# SN32F420 register map
Vendor: SONiX Technology Co., Ltd.; Series: SN32F420; File version: 1.00
CPU: CM0 r0p0, little endian, no MPU, no FPU, 2 interrupt priority bits
Registers are 32-bit, read-write, reset 0x0 unless marked. A register's access mark holds for its fields unless they carry their own. Offsets are from the block's base; [hi:lo] are bit positions; {n}, {i} and the like mark numbered series.

## SN_MT16B0 — 16-bit Timer 0 with Mortor Control function
Base 0x40000000
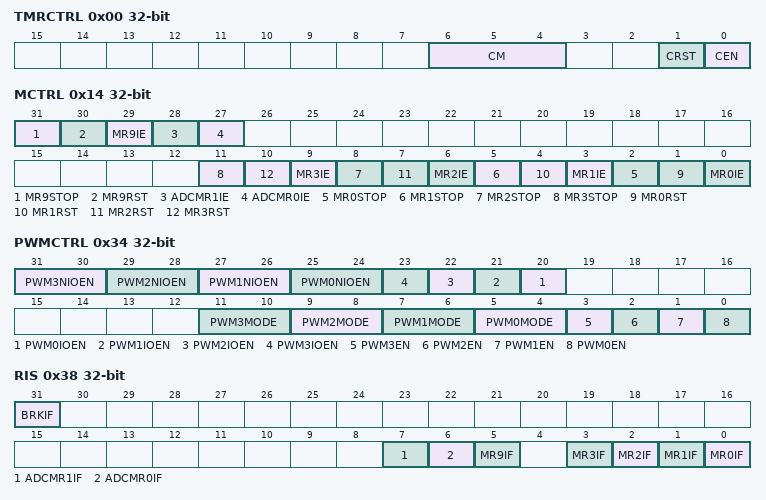
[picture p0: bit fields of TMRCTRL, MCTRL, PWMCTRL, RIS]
0x00 TMRCTRL — Offset:0x00 MT16Bn Timer Control register
  [6:4] CM — Counting mode selection
    0=Up-counting mode (Edge-aligned Up-counting mode); 2=Center-aligned counting mode 1 (The match interrupt flag is set during the down-counting period); 4=Center-aligned counting mode 2 (The match interrupt flag is set during the up-counting period); 6=Center-aligned counting mode 3 (The match interrupt flag is set during both up-counting and down-counting period)
  [1] CRST — Counter Reset
    0=Disable counter reset; 1=Reset Counter (Timer Counter and the Prescale Counter are synchronously reset on the next positive edge of PCLK)
  [0] CEN — Counter enable
    0=Disable counter; 1=Enable Timer Counter and Prescale Counter for counting
0x04 TC — Offset:0x04 MT16Bn Timer Counter register
  [15:0] TC — Timer Counter
0x08 PRE — Offset:0x08 MT16Bn Prescale register
  [7:0] PRE — Prescaler
0x0C PC — Offset:0x0C MT16Bn Prescale Counter register
  [7:0] PC — Prescaler Counter
0x14 MCTRL — Offset:0x14 MT16Bn Match Control register
  [31] MR9STOP — Stop TC and PC and clear CEN bit when MR9 matches TC
    0=Disable stop TC and PC; 1=Enable (Stop TC and PC and clear CEN bit when MR9 matches TC)
  [30] MR9RST — Enable reset TC when MR9 matches TC
    0=Disable reset TC; 1=Enable (Reset TC when MR9 matches TC)
  [29] MR9IE — Enable generating an interrupt based on CM[2:0] when MR9 matches the value in the TC
    0=Disable generating an interrupt; 1=Enable (Generating an interrupt when MR9 matches TC)
  [28] ADCMR1IE — Enable generating an interrupt based on CM[2:0] when TMR1 matches the value in the TC
    0=Disable generating an interrupt; 1=Enable (Generating an interrupt when ADCMR1 matches TC)
  [27] ADCMR0IE — Enable generating an interrupt based on CM[2:0] when TMR0 matches the value in the TC
    0=Disable generating an interrupt; 1=Enable (Generating an interrupt when ADCMR0 matches TC)
  [3n+2] MR{n}STOP (n=0..3) — Stop TC and PC and clear CEN bit when MR{n} matches TC
    0=Disable stop TC and PC; 1=Enable (Stop TC and PC and clear CEN bit when MR{n} matches TC)
  [3n+1] MR{n}RST (n=0..3) — Enable reset TC when MR{n} matches TC
    0=Disable reset TC; 1=Enable (Reset TC when MR{n} matches TC)
  [3n] MR{n}IE (n=0..3) — Enable generating an interrupt when MR{n} matches TC
    0=Disable generating an interrupt; 1=Enable (Generating an interrupt when MR{n} matches TC)
{0x18+4i} MR{i} (i=0..3) — Offset:{0x18+4i} MT16Bn MR{i} register
  [15:0] MR — Timer counter match value
0x34 PWMCTRL — Offset:0x34 MT16Bn PWM Control register
  [31:30] PWM3NIOEN — MT16Bn_PWM3N/GPIO selection bit
    0=GPIO (MT16Bn_PWM3N pin is act as GPIO); 1=Inverse1 (MT16Bn_PWM3N pin outputs the inverse signal with dead-band of MT16Bn_PWM3, but same High signal during dead-band period); 2=Inverse2 (MT16Bn_PWM3N pin outputs the inverse signal with dead-band of MT16Bn_PWM3, but same Low signal during dead-band period); 3=Same (MT16Bn_PWM3N pin outputs the same signal with dead-band of MT16Bn_PWM3)
  [29:28] PWM2NIOEN — MT16Bn_PWM0N/GPIO selection bit
    0=GPIO (MT16Bn_PWM2N pin is act as GPIO); 1=Inverse1 (MT16Bn_PWM2N pin outputs the inverse signal with dead-band of MT16Bn_PWM0, but same High signal during dead-band period); 2=Inverse2 (MT16Bn_PWM2N pin outputs the inverse signal with dead-band of MT16Bn_PWM0, but same Low signal during dead-band period); 3=Same (MT16Bn_PWM2N pin outputs the same signal with dead-band of MT16Bn_PWM0)
  [27:26] PWM1NIOEN — MT16Bn_PWM0N/GPIO selection bit
    0=GPIO (MT16Bn_PWM1N pin is act as GPIO); 1=Inverse1 (MT16Bn_PWM1N pin outputs the inverse signal with dead-band of MT16Bn_PWM0, but same High signal during dead-band period); 2=Inverse2 (MT16Bn_PWM1N pin outputs the inverse signal with dead-band of MT16Bn_PWM0, but same Low signal during dead-band period); 3=Same (MT16Bn_PWM1N pin outputs the same signal with dead-band of MT16Bn_PWM0)
  [25:24] PWM0NIOEN — MT16Bn_PWM0N/GPIO selection bit
    0=GPIO (MT16Bn_PWM0N pin is act as GPIO); 1=Inverse1 (MT16Bn_PWM0N pin outputs the inverse signal with dead-band of MT16Bn_PWM0, but same High signal during dead-band period); 2=Inverse2 (MT16Bn_PWM0N pin outputs the inverse signal with dead-band of MT16Bn_PWM0, but same Low signal during dead-band period); 3=Same (MT16Bn_PWM0N pin outputs the same signal with dead-band of MT16Bn_PWM0)
  [n+20] PWM{n}IOEN (n=0..3) — MT16Bn_PWM{n}/GPIO selection
    0=Disable (MT16Bn_PWM{n} pin is act as GPIO); 1=Enable (MT16Bn_PWM{n} pin act as match output, and output depends on PWM{n}EN bit)
  [2n+5:2n+4] PWM{n}MODE (n=0..3) — PWM{n} output mode
    0=PWM mode 1 (During up-counting, PWM{n} is 0 when TC is less than MR{n}.); 1=PWM mode 2 (During up-counting, PWM{n} is 1 when TC is less than MR{n}.); 2=Force 0 (PWM{n} is forced to 0); 3=Force 1 (PWM{n} is forced to 1)
  [3] PWM3EN — PWM2 enable
    0=Disable PWM mode for MT16Bn_PWM3; 1=Enable PWM mode for MT16Bn_PWM3
  [2] PWM2EN — PWM2 enable
    0=Disable PWM mode for MT16Bn_PWM2; 1=Enable PWM mode for MT16Bn_PWM2
  [1] PWM1EN — PWM1 enable
    0=Disable PWM mode for MT16Bn_PWM0; 1=Enable PWM mode for MT16Bn_PWM1
  [0] PWM0EN — PWM0 enable
    0=Disable PWM mode for MT16Bn_PWM0; 1=Enable PWM mode for MT16Bn_PWM0
0x38 RIS ro — Offset:0x38 MT16Bn Raw Interrupt Status register
  [31] BRKIF — Break interrupt flag
    0=No (No break condition occurs); 1=Met interrupt requirements (Break condition occurs)
  [7] ADCMR1IF — Match value for ADC triggered 1 interrupt flag
    0=No (No interrupt on match value for ADC triggered 1); 1=Met interrupt requirements (Interrupt requirements met on match value for ADC triggered 1)
  [6] ADCMR0IF — Match value for ADC triggered 0 interrupt flag
    0=No (No interrupt on match value for ADC triggered 0); 1=Met interrupt requirements (Interrupt requirements met on match value for ADC triggered 0)
  [5] MR9IF — Match channel 9 interrupt flag
    0=No (No interrupt on match channel 9); 1=Met interrupt requirements (Interrupt requirements met on match channel 9)
  [n] MR{n}IF (n=0..3) — Match channel {n} interrupt flag
    0=No (No interrupt on match channel {n}); 1=Met interrupt requirements (Interrupt requirements met on match channel {n})
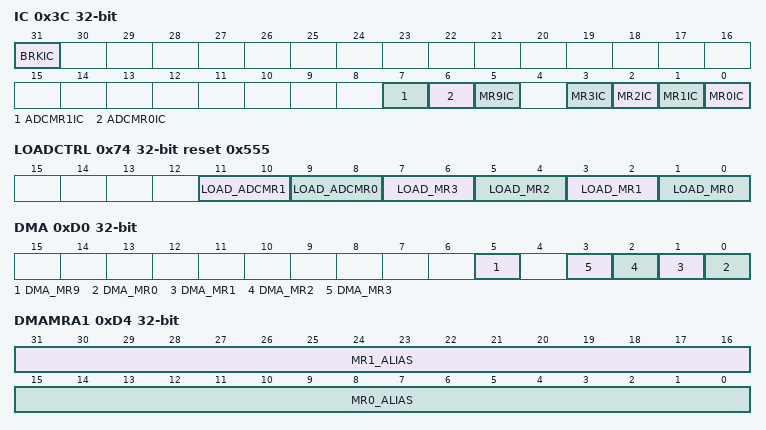
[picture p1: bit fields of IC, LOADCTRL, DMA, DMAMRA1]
0x3C IC wo — Offset:0x3C MT16Bn Interrupt Clear register
  [31] BRKIC — BRKIF clear bit
    0=None (No effect); 1=Clear BRKIF
  [7] ADCMR1IC — TADCMR1IF clear bit
    0=None (No effect); 1=Clear ADCMR1IF
  [6] ADCMR0IC — TADCMR0IF clear bit
    0=None (No effect); 1=Clear ADCMR0IF
  [5] MR9IC — MR9IF clear bit
    0=None (No effect); 1=Clear MR9IF
  [n] MR{n}IC (n=0..3) — MR{n}IF clear bit
    0=None (No effect); 1=Clear MR{n}IF
0x40 MR9 — Offset:0x40 MT16Bn MR9 register
  [15:0] MR — Timer counter match value
{0x44+4i} PWM{i}NDB (i=0..3) — Offset:{0x44+4i} MT16Bn PWM{i}N Dead-band Period register
  [9:0] DB — PWM{i}N output dead-band period time=DB*MT16Bn_PCLK*(PR+1) cycle
0x74 LOADCTRL reset 0x555 — Offset:0x74 MT16Bn PWM Load Mode Control register
  [11:10] LOAD_ADCMR1 — TADCMR1 load mode selection in center-aligned mode
    0=00b (No effect); 1=01b (Load ADCMR1 value at TC=0 and ADCMR1 value is unchanged at TC=MR9); 2=10b (ADCMR1 value is unchanged at TC=0 and Load ADCMR1 value at TC=MR9); 3=11b (Load ADCMR1 value at TC=0 and TC=MR9)
  [9:8] LOAD_ADCMR0 — TADCMR0 load mode selection in center-aligned mode
    0=00b (No effect); 1=01b (Load ADCMR0 value at TC=0 and ADCMR0 value is unchanged at TC=MR9); 2=10b (ADCMR0 value is unchanged at TC=0 and Load ADCMR0 value at TC=MR9); 3=11b (Load ADCMR0 value at TC=0 and TC=MR9)
  [7:6] LOAD_MR3 — MR3 load mode selection in center-aligned mode
    0=00b (No effect); 1=01b (Load MR3 value at TC=0 and MR3 value is unchanged at TC=MR9); 2=10b (MR3 value is unchanged at TC=0 and Load MR3 value at TC=MR9); 3=11b (Load MR3 value at TC=0 and TC=MR9)
  [5:4] LOAD_MR2 — MR2 load mode selection in center-aligned mode
    0=00b (No effect); 1=01b (Load MR2 value at TC=0 and MR2 value is unchanged at TC=MR9); 2=10b (MR2 value is unchanged at TC=0 and Load MR0 value at TC=MR9); 3=11b (Load MR2 value at TC=0 and TC=MR9)
  [3:2] LOAD_MR1 — MR1 load mode selection in center-aligned mode
    0=00b (No effect); 1=01b (Load MR1 value at TC=0 and MR1 value is unchanged at TC=MR9); 2=10b (MR1 value is unchanged at TC=0 and Load MR1 value at TC=MR9); 3=11b (Load MR1 value at TC=0 and TC=MR9)
  [1:0] LOAD_MR0 — MR0 load mode selection in center-aligned mode
    0=00b (No effect); 1=01b (Load MR0 value at TC=0 and MR0 value is unchanged at TC=MR9); 2=10b (MR0 value is unchanged at TC=0 and Load MR0 value at TC=MR9); 3=11b (Load MR0 value at TC=0 and TC=MR9)
0xD0 DMA — Offset:0xD0 MT16Bn DMA mode register
  [5] DMA_MR9 — MR9 DMA request active enable
    0=Disable. MR9 DMA request cannot issue.; 1=Enable. MR9 DMA request can issue.
  [n] DMA_MR{n} (n=0..3) — MR{n} DMA request active enable
    0=Disable. MR{n} DMA request cannot issue.; 1=Enable. MR{n} DMA request can issue.
0xD4 DMAMRA1 wo — Offset:0xD4 MT16Bn DMA MR Alias register 1
  [31:16] MR1_ALIAS — MR1 alias for DMA access
  [15:0] MR0_ALIAS — MR0 alias for DMA access
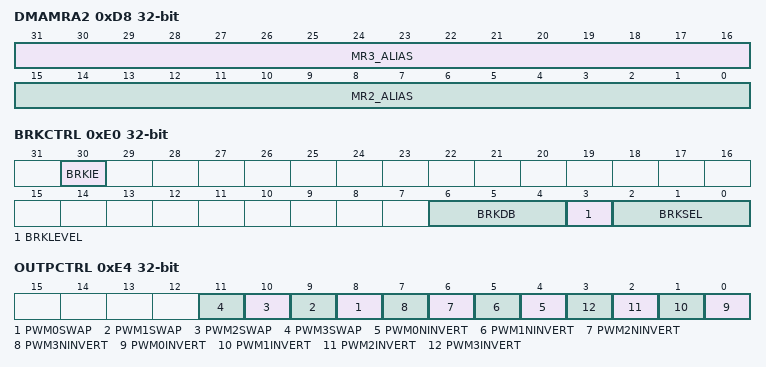
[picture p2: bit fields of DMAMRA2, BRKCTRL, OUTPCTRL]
0xD8 DMAMRA2 wo — Offset:0xD8 MT16Bn DMA MR Alias register 2
  [31:16] MR3_ALIAS — MR3 alias for DMA access
  [15:0] MR2_ALIAS — MR2 alias for DMA access
0xE0 BRKCTRL — Offset:0xE0 MT16Bn Break Function Control register
  [30] BRKIE — Enable generating an interrupt when BRKIF = 1
    0=Disable generating an interrup; 1=Enable (Generating an interrupt when BRKIF = 1)
  [6:4] BRKDB — Break pin (BRK) debounce time
    0=1T (Debounce time=1*MT16B0_PCLK); 1=2T (Debounce time=2*MT16B0_PCLK); 2=4T (Debounce time=4*MT16B0_PCLK); 3=8T (Debounce time=8*MT16B0_PCLK); 4=16T (Debounce time=16*MT16B0_PCLK); 5=32T (Debounce time=32*MT16B0_PCLK); 6=64T (Debounce time=64*MT16B0_PCLK); 7=128T (Debounce time=128*MT16B0_PCLK)
  [3] BRKLEVEL — The trigger level of PWM channels break function
    0=0b (Low level. (CMP V- > V+)); 1=1b (High level. (CMP V+ > V-))
  [2:0] BRKSEL — The trigger source selection of PWM channels break function
    0=000b (Disable); 1=001b (CMP0 output); 2=010b (CMP1 output); 4=100b (Break pin (BRK))
0xE4 OUTPCTRL — Offset:0xE4 MT16Bn Output Control register
  [n+8] PWM{n}SWAP (n=0..3) — Swap the output signal of PWM{n} and PWM{n}N
    0=Disable swap the output signal of PWM{n} and PWM{n}N; 1=Enable swap the output signal of PWM{n} and PWM{n}N
  [n+4] PWM{n}NINVERT (n=0..3) — Invert the output signal of PWM{n}N
    0=Disable invert the output signal of PWM{n}N; 1=Enable invert the output signal of PWM{n}N
  [n] PWM{n}INVERT (n=0..3) — Invert the output signal of PWM{n}
    0=Disable invert the output signal of PWM{n}; 1=Enable invert the output signal of PWM{n}
0xE8 ADCMR0 — Offset:0xE8 MT16Bn ADC Match register 0
  [15:0] ADCMR — Timer counter match value for ADC triggered
0xEC ADCMR1 — Offset:0xEC MT16Bn ADC Match register 1
  [15:0] ADCMR — Timer counter match value for ADC triggered
